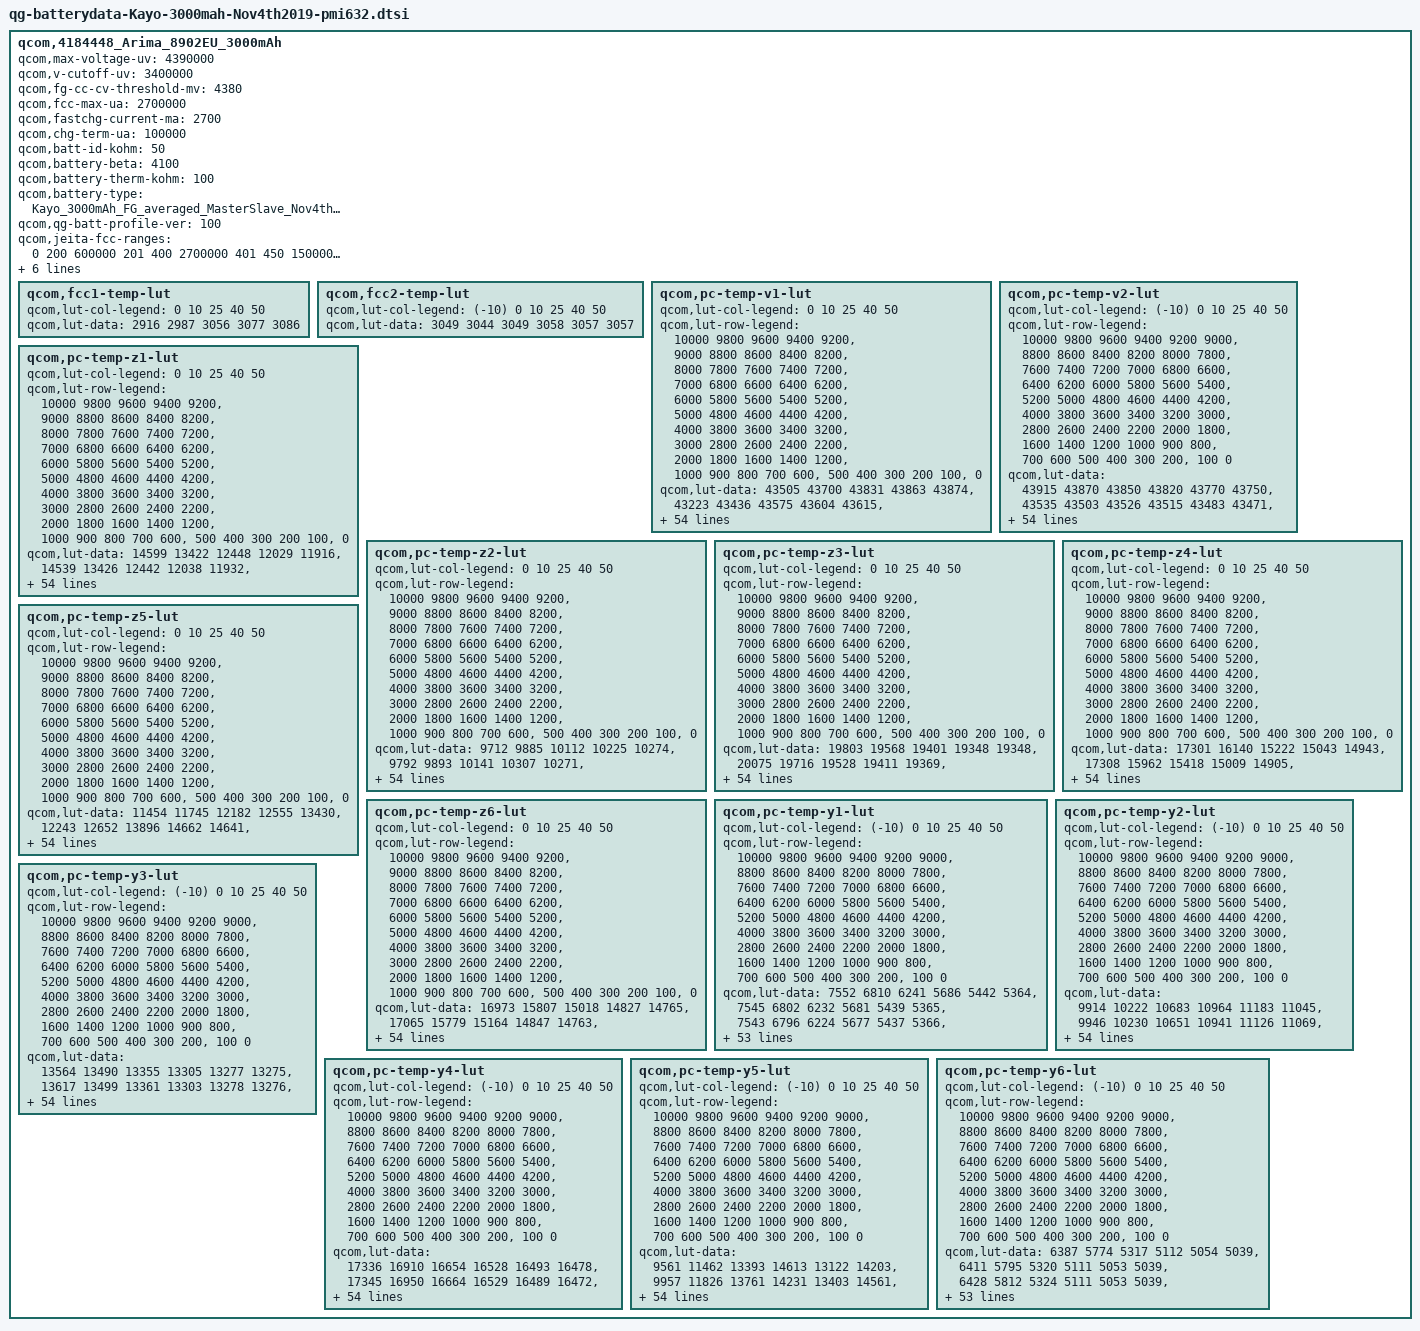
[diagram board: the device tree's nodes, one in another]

qcom,4184448_Arima_8902EU_3000mAh {
    /* 4184448_Arima_8902EU_3000mAh_averaged_MasterSlave_Nov4th2019 */
    qcom,max-voltage-uv = <4390000>;
    qcom,v-cutoff-uv = <3400000>;
    qcom,fg-cc-cv-threshold-mv = <4380>;
    qcom,fcc-max-ua = <2700000>;
    qcom,fastchg-current-ma = <2700>;
    qcom,chg-term-ua = <100000>;
    qcom,batt-id-kohm = <50>;
    qcom,battery-beta = <4100>;
    qcom,battery-therm-kohm = <100>;
    qcom,battery-type = "Kayo_3000mAh_FG_averaged_MasterSlave_Nov4th2019";
    qcom,qg-batt-profile-ver = <100>;

    qcom,jeita-fcc-ranges = <0   200   600000
                             201 400  2700000
                             401 450  1500000
                             451 550  1000000
                             551 600  0>;
    qcom,jeita-fv-ranges =  <0   200  4400000
                             201 400  4400000
                             401 450  4400000
                             451 550  4100000
                             551 600  3300000>;

    /* COOL = 20 DegC, WARM = 45 DegC */
    qcom,jeita-soft-thresholds = <0x3EBC 0x2204>;
    /* COLD = 0 DegC, HOT = 55 DegC */
    qcom,jeita-hard-thresholds = <0x5675 0x1987>;

    qcom,step-chg-ranges =  <3500000 4200000  2700000
                             4200001 4400000  1500000>;

	qcom,fcc1-temp-lut {
		qcom,lut-col-legend = <0 10 25 40 50>;
		qcom,lut-data = <2916 2987 3056 3077 3086>;
	};

	qcom,fcc2-temp-lut {
		qcom,lut-col-legend = <(-10) 0 10 25 40 50>;
		qcom,lut-data = <3049 3044 3049 3058 3057 3057>;
	};

	qcom,pc-temp-v1-lut {
		qcom,lut-col-legend = <0 10 25 40 50>;
		qcom,lut-row-legend = <10000 9800 9600 9400 9200>,
			<9000 8800 8600 8400 8200>,
			<8000 7800 7600 7400 7200>,
			<7000 6800 6600 6400 6200>,
			<6000 5800 5600 5400 5200>,
			<5000 4800 4600 4400 4200>,
			<4000 3800 3600 3400 3200>,
			<3000 2800 2600 2400 2200>,
			<2000 1800 1600 1400 1200>,
			<1000 900 800 700 600>,
			<500 400 300 200 100>,
			<0>;
		qcom,lut-data = <43505 43700 43831 43863 43874>,
			<43223 43436 43575 43604 43615>,
			<42972 43181 43325 43357 43374>,
			<42740 42936 43082 43121 43135>,
			<42513 42699 42840 42885 42899>,
			<42290 42465 42600 42648 42664>,
			<42072 42233 42363 42413 42432>,
			<41858 42006 42129 42179 42200>,
			<41647 41788 41899 41947 41970>,
			<41449 41575 41673 41719 41742>,
			<41275 41375 41449 41492 41515>,
			<41102 41200 41240 41272 41292>,
			<40890 41023 41056 41058 41076>,
			<40629 40803 40869 40853 40867>,
			<40376 40537 40638 40648 40663>,
			<40152 40296 40381 40446 40464>,
			<39950 40096 40175 40254 40274>,
			<39795 39922 40019 40078 40095>,
			<39678 39783 39875 39911 39925>,
			<39570 39672 39732 39752 39761>,
			<39450 39550 39589 39601 39607>,
			<39330 39403 39402 39421 39432>,
			<39209 39239 39142 39161 39196>,
			<39089 39046 38910 38917 38962>,
			<38970 38812 38757 38775 38807>,
			<38852 38639 38636 38670 38688>,
			<38735 38538 38540 38571 38578>,
			<38629 38463 38464 38475 38471>,
			<38529 38404 38394 38385 38374>,
			<38442 38358 38325 38300 38288>,
			<38382 38316 38262 38221 38211>,
			<38336 38275 38203 38152 38140>,
			<38298 38238 38150 38094 38075>,
			<38263 38204 38102 38040 38015>,
			<38232 38174 38062 37995 37962>,
			<38200 38141 38025 37953 37911>,
			<38170 38109 37989 37905 37853>,
			<38133 38072 37953 37854 37789>,
			<38079 38016 37902 37791 37717>,
			<38002 37926 37815 37710 37637>,
			<37909 37822 37708 37612 37545>,
			<37785 37705 37596 37502 37437>,
			<37643 37570 37468 37372 37309>,
			<37484 37410 37312 37219 37153>,
			<37344 37263 37166 37074 37009>,
			<37241 37162 37070 36982 36924>,
			<37211 37136 37044 36961 36902>,
			<37186 37117 37031 36946 36887>,
			<37160 37097 37013 36929 36872>,
			<37119 37062 36976 36885 36821>,
			<36940 36869 36767 36648 36564>,
			<36508 36448 36348 36223 36135>,
			<35949 35887 35785 35659 35574>,
			<35193 35123 35019 34892 34806>,
			<34002 33937 33832 33710 33623>,
			<30000 30000 30000 30000 30000>;
	};

	qcom,pc-temp-v2-lut {
		qcom,lut-col-legend = <(-10) 0 10 25 40 50>;
		qcom,lut-row-legend = <10000 9800 9600 9400 9200 9000>,
			<8800 8600 8400 8200 8000 7800>,
			<7600 7400 7200 7000 6800 6600>,
			<6400 6200 6000 5800 5600 5400>,
			<5200 5000 4800 4600 4400 4200>,
			<4000 3800 3600 3400 3200 3000>,
			<2800 2600 2400 2200 2000 1800>,
			<1600 1400 1200 1000 900 800>,
			<700 600 500 400 300 200>,
			<100 0>;
		qcom,lut-data = <43915 43870 43850 43820 43770 43750>,
			<43535 43503 43526 43515 43483 43471>,
			<43192 43171 43226 43231 43212 43205>,
			<42893 42880 42955 42969 42957 42954>,
			<42631 42624 42711 42728 42719 42717>,
			<42381 42377 42473 42491 42484 42483>,
			<42137 42128 42235 42256 42250 42250>,
			<41898 41886 42002 42023 42018 42018>,
			<41638 41652 41774 41795 41789 41789>,
			<41360 41423 41550 41569 41563 41564>,
			<41149 41218 41333 41347 41340 41341>,
			<41029 41055 41126 41127 41123 41123>,
			<40908 40891 40923 40915 40910 40909>,
			<40654 40662 40723 40720 40707 40705>,
			<40246 40370 40525 40536 40508 40506>,
			<39909 40095 40311 40337 40316 40315>,
			<39663 39845 40066 40107 40125 40128>,
			<39457 39615 39829 39895 39943 39949>,
			<39287 39422 39645 39742 39778 39783>,
			<39141 39249 39486 39614 39622 39623>,
			<38988 39077 39308 39444 39440 39439>,
			<38821 38900 39097 39205 39217 39219>,
			<38660 38734 38898 38976 39002 39007>,
			<38512 38588 38738 38797 38820 38826>,
			<38375 38456 38599 38642 38658 38665>,
			<38270 38332 38474 38513 38526 38532>,
			<38188 38210 38363 38405 38418 38423>,
			<38118 38110 38263 38308 38321 38325>,
			<38055 38039 38174 38217 38232 38234>,
			<37999 37982 38093 38134 38149 38150>,
			<37947 37935 38016 38061 38075 38074>,
			<37899 37897 37941 37993 38005 38002>,
			<37853 37861 37879 37930 37940 37936>,
			<37805 37827 37835 37869 37884 37880>,
			<37757 37793 37798 37812 37826 37821>,
			<37705 37751 37759 37755 37749 37733>,
			<37651 37702 37720 37698 37652 37610>,
			<37590 37647 37676 37636 37559 37500>,
			<37518 37583 37622 37565 37474 37411>,
			<37439 37509 37558 37488 37392 37328>,
			<37359 37421 37477 37410 37316 37250>,
			<37274 37316 37371 37325 37237 37170>,
			<37195 37197 37249 37215 37129 37062>,
			<37117 37071 37108 37079 36992 36926>,
			<37035 36961 36966 36930 36852 36793>,
			<36948 36867 36890 36881 36816 36763>,
			<36898 36819 36867 36867 36808 36752>,
			<36843 36772 36841 36853 36793 36736>,
			<36764 36701 36805 36823 36765 36710>,
			<36632 36595 36726 36763 36696 36625>,
			<36401 36395 36513 36551 36435 36335>,
			<36034 36017 36066 36101 35970 35860>,
			<35477 35437 35421 35504 35356 35242>,
			<34667 34604 34564 34707 34524 34396>,
			<33357 33266 33270 33533 33299 33148>,
			<29584 29579 29543 29540 29552 29553>;
	};

	qcom,pc-temp-z1-lut {
		qcom,lut-col-legend = <0 10 25 40 50>;
		qcom,lut-row-legend = <10000 9800 9600 9400 9200>,
			<9000 8800 8600 8400 8200>,
			<8000 7800 7600 7400 7200>,
			<7000 6800 6600 6400 6200>,
			<6000 5800 5600 5400 5200>,
			<5000 4800 4600 4400 4200>,
			<4000 3800 3600 3400 3200>,
			<3000 2800 2600 2400 2200>,
			<2000 1800 1600 1400 1200>,
			<1000 900 800 700 600>,
			<500 400 300 200 100>,
			<0>;
		qcom,lut-data = <14599 13422 12448 12029 11916>,
			<14539 13426 12442 12038 11932>,
			<14504 13419 12430 12034 11931>,
			<14480 13395 12421 12028 11929>,
			<14463 13354 12410 12025 11928>,
			<14447 13327 12396 12022 11929>,
			<14438 13311 12386 12020 11931>,
			<14441 13299 12379 12020 11932>,
			<14453 13289 12375 12021 11933>,
			<14459 13281 12375 12022 11934>,
			<14440 13277 12379 12022 11935>,
			<14406 13281 12381 12022 11936>,
			<14374 13285 12383 12024 11938>,
			<14335 13275 12384 12027 11941>,
			<14301 13247 12376 12027 11943>,
			<14274 13229 12357 12027 11944>,
			<14252 13221 12352 12027 11946>,
			<14250 13215 12360 12029 11948>,
			<14266 13222 12371 12033 11951>,
			<14280 13248 12379 12036 11953>,
			<14289 13268 12386 12039 11956>,
			<14303 13281 12392 12041 11958>,
			<14310 13291 12397 12042 11960>,
			<14326 13292 12401 12044 11961>,
			<14348 13290 12406 12047 11964>,
			<14369 13290 12412 12053 11968>,
			<14403 13309 12418 12058 11972>,
			<14418 13335 12424 12062 11976>,
			<14390 13338 12430 12067 11981>,
			<14356 13331 12437 12072 11985>,
			<14352 13331 12443 12077 11989>,
			<14358 13341 12450 12082 11992>,
			<14367 13353 12456 12086 11996>,
			<14380 13362 12463 12090 12000>,
			<14397 13370 12471 12095 12003>,
			<14416 13375 12480 12099 12006>,
			<14441 13382 12488 12103 12009>,
			<14462 13391 12496 12106 12011>,
			<14468 13404 12504 12109 12013>,
			<14469 13424 12511 12113 12016>,
			<14474 13437 12519 12117 12019>,
			<14490 13441 12525 12121 12022>,
			<14495 13445 12530 12125 12025>,
			<14477 13454 12538 12128 12028>,
			<14505 13478 12547 12133 12032>,
			<14495 13462 12558 12136 12033>,
			<14465 13457 12554 12138 12034>,
			<14488 13470 12557 12139 12036>,
			<14524 13460 12560 12141 12037>,
			<14513 13470 12566 12144 12040>,
			<14515 13503 12576 12150 12046>,
			<14537 13510 12589 12161 12053>,
			<14588 13546 12611 12175 12068>,
			<14625 13621 12652 12200 12088>,
			<14625 13621 12652 12200 12088>,
			<14625 13621 12652 12200 12088>;
	};

	qcom,pc-temp-z2-lut {
		qcom,lut-col-legend = <0 10 25 40 50>;
		qcom,lut-row-legend = <10000 9800 9600 9400 9200>,
			<9000 8800 8600 8400 8200>,
			<8000 7800 7600 7400 7200>,
			<7000 6800 6600 6400 6200>,
			<6000 5800 5600 5400 5200>,
			<5000 4800 4600 4400 4200>,
			<4000 3800 3600 3400 3200>,
			<3000 2800 2600 2400 2200>,
			<2000 1800 1600 1400 1200>,
			<1000 900 800 700 600>,
			<500 400 300 200 100>,
			<0>;
		qcom,lut-data = <9712 9885 10112 10225 10274>,
			<9792 9893 10141 10307 10271>,
			<9825 9895 10133 10369 10364>,
			<9845 9888 10112 10341 10395>,
			<9860 9865 10090 10310 10403>,
			<9873 9846 10063 10269 10370>,
			<9881 9834 10046 10241 10329>,
			<9879 9826 10039 10243 10320>,
			<9870 9826 10036 10252 10316>,
			<9860 9826 10044 10264 10310>,
			<9853 9827 10063 10282 10288>,
			<9843 9840 10079 10296 10267>,
			<9825 9856 10092 10291 10258>,
			<9789 9861 10105 10275 10255>,
			<9767 9862 10122 10264 10264>,
			<9768 9865 10140 10241 10282>,
			<9770 9879 10151 10233 10304>,
			<9776 9901 10158 10243 10333>,
			<9796 9923 10164 10256 10364>,
			<9810 9949 10177 10268 10383>,
			<9805 9965 10195 10282 10398>,
			<9793 9972 10203 10305 10403>,
			<9785 9976 10206 10367 10381>,
			<9781 9978 10206 10419 10355>,
			<9779 9979 10189 10387 10375>,
			<9781 9981 10163 10306 10447>,
			<9788 9986 10160 10287 10494>,
			<9795 9992 10174 10329 10528>,
			<9802 9992 10187 10361 10545>,
			<9807 9989 10205 10357 10449>,
			<9812 9987 10223 10347 10264>,
			<9815 9991 10222 10333 10218>,
			<9819 9997 10208 10311 10224>,
			<9824 10003 10201 10300 10234>,
			<9830 10008 10205 10325 10274>,
			<9838 10014 10212 10371 10343>,
			<9852 10020 10217 10413 10412>,
			<9867 10027 10226 10458 10494>,
			<9881 10036 10238 10490 10530>,
			<9895 10047 10268 10511 10526>,
			<9909 10057 10292 10523 10518>,
			<9922 10062 10289 10521 10514>,
			<9942 10068 10281 10514 10512>,
			<9986 10083 10287 10466 10501>,
			<10168 10194 10324 10440 10492>,
			<10204 10275 10381 10463 10512>,
			<10117 10323 10371 10461 10519>,
			<10078 10427 10370 10454 10521>,
			<10040 10550 10407 10447 10559>,
			<10045 10586 10407 10549 10754>,
			<10031 10491 10568 10539 10410>,
			<10023 10462 10575 10439 10280>,
			<9876 10362 10543 10309 10300>,
			<9730 10231 10462 10272 10258>,
			<9730 10231 10462 10272 10258>,
			<9730 10231 10462 10272 10258>;
	};

	qcom,pc-temp-z3-lut {
		qcom,lut-col-legend = <0 10 25 40 50>;
		qcom,lut-row-legend = <10000 9800 9600 9400 9200>,
			<9000 8800 8600 8400 8200>,
			<8000 7800 7600 7400 7200>,
			<7000 6800 6600 6400 6200>,
			<6000 5800 5600 5400 5200>,
			<5000 4800 4600 4400 4200>,
			<4000 3800 3600 3400 3200>,
			<3000 2800 2600 2400 2200>,
			<2000 1800 1600 1400 1200>,
			<1000 900 800 700 600>,
			<500 400 300 200 100>,
			<0>;
		qcom,lut-data = <19803 19568 19401 19348 19348>,
			<20075 19716 19528 19411 19369>,
			<20081 19811 19562 19454 19411>,
			<20062 19834 19578 19464 19433>,
			<20034 19844 19582 19468 19440>,
			<19966 19847 19584 19469 19440>,
			<19907 19848 19584 19470 19440>,
			<19901 19848 19574 19463 19434>,
			<19900 19843 19559 19448 19417>,
			<19900 19825 19547 19436 19406>,
			<19899 19804 19534 19427 19401>,
			<19898 19774 19526 19420 19396>,
			<19910 19745 19516 19414 19385>,
			<19966 19736 19507 19404 19372>,
			<20004 19733 19504 19397 19367>,
			<19994 19728 19503 19385 19365>,
			<19971 19712 19499 19378 19363>,
			<19943 19687 19487 19377 19355>,
			<19899 19665 19475 19375 19344>,
			<19869 19642 19470 19374 19342>,
			<19877 19632 19466 19372 19342>,
			<19901 19647 19469 19372 19343>,
			<19923 19671 19495 19388 19349>,
			<19942 19689 19514 19404 19356>,
			<19958 19707 19506 19392 19349>,
			<19971 19715 19491 19363 19328>,
			<19982 19714 19480 19354 19324>,
			<19987 19712 19471 19361 19367>,
			<19987 19708 19467 19371 19406>,
			<19986 19700 19472 19393 19402>,
			<19981 19693 19482 19420 19389>,
			<19964 19687 19491 19424 19380>,
			<19944 19681 19501 19417 19375>,
			<19927 19674 19505 19408 19370>,
			<19909 19667 19502 19400 19364>,
			<19887 19661 19496 19393 19359>,
			<19857 19654 19490 19391 19359>,
			<19833 19648 19482 19390 19361>,
			<19823 19645 19476 19388 19361>,
			<19817 19642 19472 19384 19360>,
			<19809 19639 19469 19380 19357>,
			<19799 19633 19467 19379 19354>,
			<19782 19623 19464 19379 19350>,
			<19746 19608 19456 19370 19351>,
			<19539 19554 19438 19361 19350>,
			<19448 19517 19424 19359 19336>,
			<19360 19487 19421 19353 19336>,
			<19338 19415 19383 19350 19334>,
			<19334 19359 19380 19350 19322>,
			<19331 19356 19379 19342 19311>,
			<19336 19407 19355 19344 19349>,
			<19363 19368 19347 19351 19359>,
			<19378 19358 19345 19361 19341>,
			<19370 19355 19344 19360 19341>,
			<19370 19355 19344 19360 19341>,
			<19370 19355 19344 19360 19341>;
	};

	qcom,pc-temp-z4-lut {
		qcom,lut-col-legend = <0 10 25 40 50>;
		qcom,lut-row-legend = <10000 9800 9600 9400 9200>,
			<9000 8800 8600 8400 8200>,
			<8000 7800 7600 7400 7200>,
			<7000 6800 6600 6400 6200>,
			<6000 5800 5600 5400 5200>,
			<5000 4800 4600 4400 4200>,
			<4000 3800 3600 3400 3200>,
			<3000 2800 2600 2400 2200>,
			<2000 1800 1600 1400 1200>,
			<1000 900 800 700 600>,
			<500 400 300 200 100>,
			<0>;
		qcom,lut-data = <17301 16140 15222 15043 14943>,
			<17308 15962 15418 15009 14905>,
			<17122 15786 15328 15050 14950>,
			<16727 15606 15162 14976 14903>,
			<16433 15424 15062 14917 14859>,
			<16251 15281 14992 14877 14826>,
			<16097 15174 14938 14845 14801>,
			<15952 15090 14895 14822 14787>,
			<15818 15031 14862 14805 14779>,
			<15698 14987 14843 14793 14770>,
			<15592 14949 14829 14783 14761>,
			<15496 14907 14817 14775 14753>,
			<15401 14876 14803 14767 14749>,
			<15307 14870 14793 14758 14746>,
			<15235 14869 14788 14757 14740>,
			<15190 14866 14784 14753 14727>,
			<15156 14857 14776 14747 14716>,
			<15122 14842 14753 14733 14710>,
			<15093 14830 14734 14716 14706>,
			<15061 14817 14728 14709 14701>,
			<15019 14806 14725 14705 14695>,
			<14971 14793 14734 14708 14694>,
			<14933 14784 14809 14785 14760>,
			<14900 14807 14876 14871 14845>,
			<14879 14900 14900 14891 14870>,
			<14875 14951 14915 14901 14882>,
			<14873 14946 14914 14901 14881>,
			<14874 14934 14897 14876 14817>,
			<14882 14919 14874 14840 14752>,
			<14892 14896 14848 14796 14738>,
			<14893 14874 14819 14748 14730>,
			<14887 14854 14793 14729 14721>,
			<14880 14837 14768 14720 14708>,
			<14873 14820 14753 14716 14702>,
			<14865 14805 14745 14714 14702>,
			<14862 14792 14740 14713 14703>,
			<14861 14779 14737 14715 14707>,
			<14860 14769 14734 14723 14723>,
			<14851 14768 14734 14731 14732>,
			<14832 14769 14745 14740 14734>,
			<14825 14770 14755 14747 14735>,
			<14824 14765 14748 14740 14731>,
			<14823 14760 14735 14728 14721>,
			<14824 14761 14737 14735 14723>,
			<14909 14753 14731 14734 14720>,
			<14962 14738 14704 14705 14702>,
			<15055 14759 14693 14694 14688>,
			<15069 14828 14716 14674 14667>,
			<15067 14881 14704 14652 14654>,
			<15059 14879 14702 14660 14665>,
			<15048 14832 14755 14694 14659>,
			<15060 14897 14775 14692 14655>,
			<15071 14921 14782 14684 14675>,
			<15107 14937 14788 14688 14676>,
			<15107 14937 14788 14688 14676>,
			<15107 14937 14788 14688 14676>;
	};

	qcom,pc-temp-z5-lut {
		qcom,lut-col-legend = <0 10 25 40 50>;
		qcom,lut-row-legend = <10000 9800 9600 9400 9200>,
			<9000 8800 8600 8400 8200>,
			<8000 7800 7600 7400 7200>,
			<7000 6800 6600 6400 6200>,
			<6000 5800 5600 5400 5200>,
			<5000 4800 4600 4400 4200>,
			<4000 3800 3600 3400 3200>,
			<3000 2800 2600 2400 2200>,
			<2000 1800 1600 1400 1200>,
			<1000 900 800 700 600>,
			<500 400 300 200 100>,
			<0>;
		qcom,lut-data = <11454 11745 12182 12555 13430>,
			<12243 12652 13896 14662 14641>,
			<12436 13367 14441 15536 15665>,
			<12532 13830 14827 15834 16844>,
			<12552 14152 15222 16091 17560>,
			<12527 14535 15609 16368 17875>,
			<12502 15138 15928 16601 18050>,
			<12551 15743 16212 16735 17898>,
			<12726 16087 16403 16725 17371>,
			<12887 16332 16498 16662 17155>,
			<12979 16550 16698 16583 17268>,
			<13082 16850 16825 16576 17355>,
			<13409 17177 17092 16656 16992>,
			<14282 17631 17333 16659 16294>,
			<14830 18572 17534 16467 16225>,
			<14822 19041 18085 15934 16905>,
			<14790 18616 18533 15813 17373>,
			<14713 18031 18902 16522 17104>,
			<14449 17791 19349 17525 16697>,
			<14245 17646 19899 18215 16853>,
			<14598 17636 20709 18771 17988>,
			<15691 20478 23295 19826 18918>,
			<17030 25517 32932 23676 19820>,
			<18860 30303 39368 27018 20550>,
			<21143 35691 34703 24339 19129>,
			<23928 38044 26187 17537 15121>,
			<27393 36280 21987 15112 13807>,
			<30042 33236 19473 14804 16059>,
			<32020 30881 18529 14686 18244>,
			<33389 28692 18785 16275 18450>,
			<33081 27358 19394 19654 18492>,
			<30672 26749 20802 21861 18808>,
			<28094 26332 24167 23393 20141>,
			<26285 26063 26973 24608 21754>,
			<24607 25796 29058 25724 23548>,
			<22853 25708 30393 26520 25129>,
			<20734 25757 30186 26653 25308>,
			<19445 25839 29114 26586 25032>,
			<19728 26174 27935 26310 24544>,
			<20483 27216 26468 23530 22587>,
			<20945 27813 25238 20623 20253>,
			<21181 26835 24812 20503 19350>,
			<21204 25242 24404 20657 18824>,
			<20042 23391 22263 18651 18178>,
			<15624 21181 21039 17430 17655>,
			<13453 19868 21195 18547 16954>,
			<11648 17113 21109 18133 17459>,
			<11421 13549 15913 18875 18995>,
			<11379 12104 15838 21530 18855>,
			<11375 12108 15893 19283 16193>,
			<11506 13512 13714 15340 18602>,
			<11658 12181 12915 15355 19788>,
			<11612 11862 12663 15997 15501>,
			<11332 11678 12471 15399 15001>,
			<11332 11678 12471 15399 15001>,
			<11332 11678 12471 15399 15001>;
	};

	qcom,pc-temp-z6-lut {
		qcom,lut-col-legend = <0 10 25 40 50>;
		qcom,lut-row-legend = <10000 9800 9600 9400 9200>,
			<9000 8800 8600 8400 8200>,
			<8000 7800 7600 7400 7200>,
			<7000 6800 6600 6400 6200>,
			<6000 5800 5600 5400 5200>,
			<5000 4800 4600 4400 4200>,
			<4000 3800 3600 3400 3200>,
			<3000 2800 2600 2400 2200>,
			<2000 1800 1600 1400 1200>,
			<1000 900 800 700 600>,
			<500 400 300 200 100>,
			<0>;
		qcom,lut-data = <16973 15807 15018 14827 14765>,
			<17065 15779 15164 14847 14763>,
			<16980 15735 15135 14883 14799>,
			<16753 15671 15074 14859 14791>,
			<16567 15579 15033 14838 14782>,
			<16430 15503 15001 14823 14772>,
			<16316 15449 14974 14808 14760>,
			<16229 15404 14948 14793 14748>,
			<16160 15366 14926 14779 14736>,
			<16098 15334 14911 14767 14727>,
			<16041 15303 14899 14759 14720>,
			<15989 15268 14889 14751 14714>,
			<15949 15238 14879 14743 14707>,
			<15916 15223 14869 14736 14699>,
			<15884 15215 14863 14729 14692>,
			<15850 15206 14857 14722 14686>,
			<15816 15191 14849 14715 14680>,
			<15783 15173 14834 14707 14673>,
			<15748 15158 14822 14701 14666>,
			<15725 15144 14818 14697 14663>,
			<15719 15138 14816 14695 14660>,
			<15716 15143 14822 14696 14660>,
			<15716 15153 14871 14740 14695>,
			<15717 15177 14908 14785 14735>,
			<15720 15227 14913 14785 14738>,
			<15724 15253 14914 14778 14736>,
			<15733 15252 14911 14772 14734>,
			<15741 15248 14900 14765 14730>,
			<15748 15243 14889 14758 14724>,
			<15754 15231 14882 14752 14717>,
			<15753 15219 14876 14746 14708>,
			<15745 15210 14870 14740 14699>,
			<15735 15201 14866 14733 14692>,
			<15727 15194 14862 14727 14686>,
			<15719 15186 14858 14722 14683>,
			<15710 15181 14855 14718 14680>,
			<15700 15176 14851 14718 14682>,
			<15693 15173 14847 14721 14689>,
			<15690 15173 14846 14724 14694>,
			<15687 15178 14850 14725 14694>,
			<15687 15181 14854 14727 14693>,
			<15688 15180 14851 14725 14690>,
			<15688 15179 14846 14720 14685>,
			<15677 15176 14844 14719 14686>,
			<15623 15154 14835 14714 14685>,
			<15600 15133 14818 14701 14671>,
			<15596 15128 14812 14694 14664>,
			<15593 15123 14803 14684 14654>,
			<15591 15118 14797 14674 14642>,
			<15592 15120 14796 14674 14642>,
			<15601 15133 14809 14690 14660>,
			<15634 15150 14818 14696 14667>,
			<15666 15168 14825 14701 14669>,
			<15707 15193 14837 14707 14674>,
			<15707 15193 14837 14707 14674>,
			<15707 15193 14837 14707 14674>;
	};

	qcom,pc-temp-y1-lut {
		qcom,lut-col-legend = <(-10) 0 10 25 40 50>;
		qcom,lut-row-legend = <10000 9800 9600 9400 9200 9000>,
			<8800 8600 8400 8200 8000 7800>,
			<7600 7400 7200 7000 6800 6600>,
			<6400 6200 6000 5800 5600 5400>,
			<5200 5000 4800 4600 4400 4200>,
			<4000 3800 3600 3400 3200 3000>,
			<2800 2600 2400 2200 2000 1800>,
			<1600 1400 1200 1000 900 800>,
			<700 600 500 400 300 200>,
			<100 0>;
		qcom,lut-data = <7552 6810 6241 5686 5442 5364>,
			<7545 6802 6232 5681 5439 5365>,
			<7543 6796 6224 5677 5437 5366>,
			<7546 6794 6215 5672 5434 5367>,
			<7553 6793 6208 5668 5432 5367>,
			<7561 6793 6202 5664 5430 5367>,
			<7572 6804 6199 5660 5429 5367>,
			<7581 6819 6195 5656 5427 5366>,
			<7576 6820 6192 5654 5427 5366>,
			<7550 6812 6189 5652 5426 5366>,
			<7540 6808 6187 5649 5425 5367>,
			<7553 6811 6186 5648 5425 5367>,
			<7568 6816 6186 5646 5424 5367>,
			<7570 6816 6186 5644 5424 5368>,
			<7562 6813 6184 5642 5424 5370>,
			<7564 6815 6183 5642 5425 5371>,
			<7576 6837 6188 5650 5426 5372>,
			<7587 6859 6195 5657 5427 5373>,
			<7588 6854 6198 5656 5427 5373>,
			<7579 6834 6203 5655 5428 5373>,
			<7572 6826 6206 5655 5429 5374>,
			<7556 6818 6208 5656 5431 5375>,
			<7544 6814 6209 5658 5432 5375>,
			<7553 6824 6207 5662 5434 5377>,
			<7570 6842 6203 5666 5435 5380>,
			<7573 6846 6202 5670 5437 5381>,
			<7567 6832 6209 5674 5440 5383>,
			<7559 6821 6217 5679 5443 5384>,
			<7555 6821 6225 5684 5445 5386>,
			<7555 6822 6231 5690 5448 5388>,
			<7553 6823 6235 5695 5451 5390>,
			<7541 6824 6242 5700 5455 5393>,
			<7532 6824 6249 5706 5458 5396>,
			<7541 6826 6256 5712 5461 5399>,
			<7554 6829 6262 5718 5464 5401>,
			<7555 6829 6265 5725 5467 5403>,
			<7551 6826 6262 5734 5471 5405>,
			<7546 6825 6258 5738 5474 5408>,
			<7535 6832 6263 5739 5475 5411>,
			<7526 6841 6270 5740 5476 5414>,
			<7539 6844 6274 5742 5479 5415>,
			<7576 6860 6278 5746 5482 5415>,
			<7552 6858 6295 5752 5483 5416>,
			<7527 6841 6309 5758 5486 5418>,
			<7601 6836 6293 5763 5490 5421>,
			<7546 6867 6308 5765 5492 5421>,
			<7555 6871 6310 5772 5494 5424>,
			<7582 6861 6320 5779 5494 5424>,
			<7584 6849 6325 5788 5497 5425>,
			<7612 6861 6321 5791 5498 5425>,
			<7599 6858 6326 5796 5500 5427>,
			<7691 6876 6346 5806 5508 5435>,
			<7678 6902 6371 5830 5519 5444>,
			<7757 6955 6381 5870 5536 5456>,
			<7757 6955 6381 5870 5536 5456>,
			<7757 6955 6381 5870 5536 5456>;
	};

	qcom,pc-temp-y2-lut {
		qcom,lut-col-legend = <(-10) 0 10 25 40 50>;
		qcom,lut-row-legend = <10000 9800 9600 9400 9200 9000>,
			<8800 8600 8400 8200 8000 7800>,
			<7600 7400 7200 7000 6800 6600>,
			<6400 6200 6000 5800 5600 5400>,
			<5200 5000 4800 4600 4400 4200>,
			<4000 3800 3600 3400 3200 3000>,
			<2800 2600 2400 2200 2000 1800>,
			<1600 1400 1200 1000 900 800>,
			<700 600 500 400 300 200>,
			<100 0>;
		qcom,lut-data = <9914 10222 10683 10964 11183 11045>,
			<9946 10230 10651 10941 11126 11069>,
			<9983 10240 10621 10918 11071 11067>,
			<10020 10249 10593 10895 11020 11052>,
			<10050 10257 10567 10872 10975 11035>,
			<10068 10262 10544 10849 10941 11028>,
			<10074 10265 10523 10825 10911 11019>,
			<10079 10267 10506 10802 10890 11002>,
			<10101 10266 10496 10774 10887 10976>,
			<10158 10263 10488 10742 10895 10930>,
			<10213 10263 10483 10729 10900 10910>,
			<10266 10342 10478 10738 10902 10910>,
			<10305 10434 10476 10748 10902 10910>,
			<10314 10433 10492 10751 10898 10920>,
			<10318 10403 10543 10754 10887 10947>,
			<10326 10392 10576 10759 10885 10954>,
			<10351 10419 10589 10776 10908 10926>,
			<10387 10455 10601 10800 10946 10901>,
			<10432 10476 10615 10843 10994 10928>,
			<10484 10492 10630 10897 11052 10992>,
			<10484 10511 10647 10908 11086 11025>,
			<10286 10534 10664 10894 11107 11052>,
			<10094 10558 10683 10883 11119 11075>,
			<9952 10585 10701 10892 11121 11108>,
			<9736 10611 10721 10911 11120 11155>,
			<9680 10616 10741 10926 11122 11189>,
			<9673 10605 10765 10949 11123 11222>,
			<9668 10592 10780 10972 11125 11238>,
			<9666 10579 10784 10989 11140 11234>,
			<9664 10561 10786 11002 11163 11228>,
			<9663 10538 10790 11008 11178 11230>,
			<9661 10508 10798 11010 11191 11244>,
			<9660 10466 10803 11011 11200 11260>,
			<9659 10335 10790 11004 11211 11279>,
			<9658 10135 10767 10993 11219 11295>,
			<9657 10006 10747 10986 11196 11289>,
			<9655 9805 10727 10977 11126 11262>,
			<9655 9695 10703 10967 11096 11241>,
			<9654 9677 10673 10957 11113 11231>,
			<9653 9667 10636 10946 11131 11227>,
			<9653 9661 10595 10934 11116 11220>,
			<9652 9658 10547 10920 11077 11193>,
			<9652 9656 10487 10904 11077 11137>,
			<9652 9653 10419 10885 11093 11129>,
			<9651 9652 10290 10865 11083 11158>,
			<9651 9652 10140 10837 11039 11066>,
			<9651 9651 10260 10820 10979 10993>,
			<9651 9651 10216 10799 10953 10940>,
			<9651 9651 10188 10795 10964 10908>,
			<9650 9650 10170 10774 10960 10865>,
			<9650 9650 10144 10741 10924 10853>,
			<9649 9650 9941 10682 10864 10805>,
			<9648 9649 9709 10605 10800 10758>,
			<9647 9648 9665 10555 10732 10653>,
			<9647 9648 9665 10555 10732 10653>,
			<9647 9648 9665 10555 10732 10653>;
	};

	qcom,pc-temp-y3-lut {
		qcom,lut-col-legend = <(-10) 0 10 25 40 50>;
		qcom,lut-row-legend = <10000 9800 9600 9400 9200 9000>,
			<8800 8600 8400 8200 8000 7800>,
			<7600 7400 7200 7000 6800 6600>,
			<6400 6200 6000 5800 5600 5400>,
			<5200 5000 4800 4600 4400 4200>,
			<4000 3800 3600 3400 3200 3000>,
			<2800 2600 2400 2200 2000 1800>,
			<1600 1400 1200 1000 900 800>,
			<700 600 500 400 300 200>,
			<100 0>;
		qcom,lut-data = <13564 13490 13355 13305 13277 13275>,
			<13617 13499 13361 13303 13278 13276>,
			<13666 13512 13367 13302 13280 13277>,
			<13707 13527 13372 13301 13282 13278>,
			<13735 13539 13377 13301 13283 13279>,
			<13744 13545 13381 13302 13284 13280>,
			<13734 13546 13384 13303 13284 13281>,
			<13717 13547 13386 13304 13285 13282>,
			<13707 13555 13388 13304 13285 13283>,
			<13699 13577 13389 13302 13285 13283>,
			<13686 13587 13391 13302 13286 13283>,
			<13638 13554 13394 13308 13290 13283>,
			<13591 13513 13397 13316 13295 13283>,
			<13592 13504 13398 13319 13295 13285>,
			<13607 13500 13401 13321 13294 13289>,
			<13611 13496 13402 13322 13294 13291>,
			<13582 13489 13399 13324 13296 13289>,
			<13549 13479 13393 13326 13298 13288>,
			<13536 13470 13388 13326 13300 13289>,
			<13527 13460 13382 13327 13301 13291>,
			<13514 13451 13375 13326 13301 13292>,
			<13488 13442 13368 13321 13297 13288>,
			<13467 13432 13361 13315 13293 13283>,
			<13461 13421 13356 13309 13288 13280>,
			<13459 13409 13352 13303 13284 13278>,
			<13456 13398 13348 13301 13282 13277>,
			<13449 13388 13344 13300 13281 13277>,
			<13445 13380 13342 13300 13281 13276>,
			<13452 13373 13342 13300 13282 13277>,
			<13468 13368 13344 13301 13283 13278>,
			<13489 13368 13343 13302 13284 13278>,
			<13523 13374 13338 13306 13284 13278>,
			<13561 13381 13335 13307 13284 13278>,
			<13598 13391 13338 13307 13285 13279>,
			<13641 13402 13343 13307 13286 13280>,
			<13695 13412 13344 13306 13286 13279>,
			<13766 13428 13344 13306 13285 13277>,
			<13844 13447 13344 13305 13285 13276>,
			<13929 13471 13348 13303 13283 13276>,
			<14023 13502 13352 13301 13282 13276>,
			<14128 13548 13355 13300 13282 13277>,
			<14249 13625 13357 13300 13284 13278>,
			<14381 13738 13361 13300 13284 13278>,
			<14524 13900 13364 13301 13283 13278>,
			<14576 14042 13355 13301 13282 13277>,
			<14696 14187 13357 13304 13281 13279>,
			<14828 14350 13379 13307 13288 13282>,
			<14982 14536 13393 13314 13290 13285>,
			<15128 14688 13413 13314 13293 13290>,
			<15291 14820 13436 13324 13301 13291>,
			<15495 14916 13453 13326 13297 13287>,
			<16003 15021 13463 13324 13297 13287>,
			<16900 15292 13520 13334 13299 13291>,
			<18414 16030 13693 13348 13304 13295>,
			<18414 16030 13693 13348 13304 13295>,
			<18414 16030 13693 13348 13304 13295>;
	};

	qcom,pc-temp-y4-lut {
		qcom,lut-col-legend = <(-10) 0 10 25 40 50>;
		qcom,lut-row-legend = <10000 9800 9600 9400 9200 9000>,
			<8800 8600 8400 8200 8000 7800>,
			<7600 7400 7200 7000 6800 6600>,
			<6400 6200 6000 5800 5600 5400>,
			<5200 5000 4800 4600 4400 4200>,
			<4000 3800 3600 3400 3200 3000>,
			<2800 2600 2400 2200 2000 1800>,
			<1600 1400 1200 1000 900 800>,
			<700 600 500 400 300 200>,
			<100 0>;
		qcom,lut-data = <17336 16910 16654 16528 16493 16478>,
			<17345 16950 16664 16529 16489 16472>,
			<17360 17005 16676 16531 16486 16469>,
			<17381 17063 16687 16534 16484 16467>,
			<17406 17111 16697 16537 16484 16466>,
			<17436 17135 16702 16541 16484 16466>,
			<17481 17143 16704 16544 16486 16467>,
			<17521 17148 16706 16548 16491 16469>,
			<17513 17139 16712 16557 16497 16473>,
			<17470 17104 16727 16572 16504 16478>,
			<17459 17092 16742 16580 16508 16483>,
			<17755 17309 16753 16581 16509 16491>,
			<18088 17561 16766 16582 16510 16498>,
			<17958 17551 16815 16591 16517 16502>,
			<17483 17428 16913 16615 16533 16505>,
			<17227 17302 16949 16639 16547 16510>,
			<17152 17162 16927 16660 16558 16522>,
			<17111 17048 16899 16684 16570 16539>,
			<17097 17011 16885 16729 16597 16559>,
			<17088 16991 16873 16782 16631 16581>,
			<17080 16960 16846 16784 16637 16584>,
			<17062 16899 16748 16691 16606 16566>,
			<17049 16842 16657 16597 16566 16541>,
			<17037 16811 16626 16552 16527 16511>,
			<17009 16787 16606 16520 16491 16481>,
			<17003 16757 16600 16515 16484 16475>,
			<17010 16710 16599 16517 16487 16477>,
			<17017 16681 16598 16519 16491 16481>,
			<17024 16688 16598 16523 16497 16486>,
			<17030 16703 16597 16529 16505 16495>,
			<17032 16714 16595 16536 16516 16504>,
			<17032 16722 16591 16544 16529 16517>,
			<17032 16731 16588 16551 16542 16529>,
			<17037 16752 16591 16558 16557 16544>,
			<17043 16787 16596 16562 16569 16556>,
			<17045 16818 16605 16560 16557 16543>,
			<17047 16862 16620 16550 16515 16500>,
			<17047 16896 16633 16539 16491 16478>,
			<17044 16920 16644 16524 16483 16474>,
			<17040 16937 16653 16513 16480 16472>,
			<17042 16938 16659 16518 16485 16476>,
			<17050 16933 16664 16530 16495 16484>,
			<17067 16920 16673 16537 16496 16484>,
			<17092 16909 16677 16539 16494 16481>,
			<17104 16907 16671 16514 16472 16460>,
			<17107 16918 16696 16522 16490 16475>,
			<17141 16963 16691 16540 16499 16485>,
			<17180 17018 16736 16559 16512 16499>,
			<17223 17102 16796 16588 16529 16521>,
			<17257 17205 16887 16618 16545 16531>,
			<17284 17261 16939 16607 16502 16483>,
			<17442 17263 16943 16591 16494 16478>,
			<17801 17305 16996 16625 16510 16492>,
			<18794 17772 17141 16709 16559 16537>,
			<18794 17772 17141 16709 16559 16537>,
			<18794 17772 17141 16709 16559 16537>;
	};

	qcom,pc-temp-y5-lut {
		qcom,lut-col-legend = <(-10) 0 10 25 40 50>;
		qcom,lut-row-legend = <10000 9800 9600 9400 9200 9000>,
			<8800 8600 8400 8200 8000 7800>,
			<7600 7400 7200 7000 6800 6600>,
			<6400 6200 6000 5800 5600 5400>,
			<5200 5000 4800 4600 4400 4200>,
			<4000 3800 3600 3400 3200 3000>,
			<2800 2600 2400 2200 2000 1800>,
			<1600 1400 1200 1000 900 800>,
			<700 600 500 400 300 200>,
			<100 0>;
		qcom,lut-data = <9561 11462 13393 14613 13122 14203>,
			<9957 11826 13761 14231 13403 14561>,
			<10618 12421 14121 13799 13565 14776>,
			<11343 13062 14429 13377 13638 14881>,
			<11936 13568 14640 13030 13650 14906>,
			<12198 13754 14711 12818 13629 14882>,
			<12254 13708 14658 12725 13485 14774>,
			<12284 13647 14543 12646 13248 14586>,
			<12201 13889 14333 12429 12994 14346>,
			<11891 14806 13915 12024 12697 14004>,
			<11748 15214 13562 11873 12606 13650>,
			<11989 13951 13266 12314 13123 13214>,
			<12478 12499 13067 12783 13673 12899>,
			<13614 13075 13078 12724 13468 13090>,
			<15670 15217 13175 12491 12829 13652>,
			<16335 16082 13356 12416 12608 13810>,
			<14952 15650 14131 12486 12710 13221>,
			<13612 15209 15044 12618 12838 12684>,
			<13802 15292 15557 12917 12912 12716>,
			<14381 15573 15951 13533 12986 12878>,
			<14504 15710 16197 14452 13314 13166>,
			<13761 15755 16381 16253 14962 13950>,
			<12935 15775 16472 17409 16182 14687>,
			<12235 15674 16267 16729 15958 15068>,
			<11340 15417 15775 15439 15458 15333>,
			<11015 15120 15370 14948 15046 15286>,
			<10875 14344 14909 14766 14607 14758>,
			<10796 13500 14656 14670 14389 14416>,
			<10768 12866 15021 14698 14575 14530>,
			<10751 12339 15579 14865 14855 14693>,
			<10767 12262 15511 15302 14928 14662>,
			<10867 12492 14847 16313 14894 14420>,
			<10973 12673 14461 16966 14961 14292>,
			<11046 12827 14863 17184 15410 14669>,
			<11116 12947 15446 17313 16009 15211>,
			<11204 12748 15461 17316 16488 15448>,
			<11313 12067 15082 17145 16940 15612>,
			<11359 11737 14859 16910 17040 15654>,
			<11304 11697 15027 16281 16164 15541>,
			<11202 11634 15240 15482 15226 15343>,
			<11077 11632 15141 14907 15093 15094>,
			<10923 11665 14782 14443 15099 14773>,
			<10879 11630 14532 14078 14642 14517>,
			<10913 11485 14265 14000 14412 14404>,
			<10872 11371 13177 14806 15169 15860>,
			<11038 11318 12659 14742 13466 14171>,
			<11078 11212 13426 14374 14372 13964>,
			<11252 11405 13433 14745 13876 14003>,
			<11425 11431 13705 13712 13947 14775>,
			<11572 11839 14106 14341 15142 14609>,
			<11569 12340 14307 15209 16090 15443>,
			<11194 12346 13428 15199 17270 15675>,
			<10507 11656 11893 15949 16875 17050>,
			<9839 10544 11476 16641 17739 18076>,
			<9839 10544 11476 16641 17739 18076>,
			<9839 10544 11476 16641 17739 18076>;
	};

	qcom,pc-temp-y6-lut {
		qcom,lut-col-legend = <(-10) 0 10 25 40 50>;
		qcom,lut-row-legend = <10000 9800 9600 9400 9200 9000>,
			<8800 8600 8400 8200 8000 7800>,
			<7600 7400 7200 7000 6800 6600>,
			<6400 6200 6000 5800 5600 5400>,
			<5200 5000 4800 4600 4400 4200>,
			<4000 3800 3600 3400 3200 3000>,
			<2800 2600 2400 2200 2000 1800>,
			<1600 1400 1200 1000 900 800>,
			<700 600 500 400 300 200>,
			<100 0>;
		qcom,lut-data = <6387 5774 5317 5112 5054 5039>,
			<6411 5795 5320 5111 5053 5039>,
			<6428 5812 5324 5111 5053 5039>,
			<6437 5825 5327 5111 5053 5039>,
			<6442 5832 5330 5112 5054 5040>,
			<6443 5834 5331 5112 5055 5040>,
			<6439 5829 5330 5114 5056 5042>,
			<6429 5822 5329 5115 5058 5043>,
			<6412 5817 5329 5117 5060 5044>,
			<6381 5813 5332 5119 5061 5046>,
			<6369 5812 5334 5122 5064 5048>,
			<6420 5844 5337 5126 5067 5050>,
			<6476 5880 5341 5131 5070 5052>,
			<6446 5873 5355 5137 5073 5055>,
			<6336 5837 5382 5144 5077 5059>,
			<6270 5799 5392 5152 5080 5062>,
			<6242 5757 5384 5160 5085 5065>,
			<6227 5722 5373 5168 5090 5068>,
			<6231 5707 5366 5181 5099 5075>,
			<6242 5698 5358 5196 5110 5083>,
			<6244 5686 5345 5196 5111 5084>,
			<6237 5667 5312 5166 5099 5076>,
			<6231 5652 5283 5134 5084 5065>,
			<6231 5645 5271 5117 5069 5054>,
			<6236 5640 5264 5104 5056 5043>,
			<6245 5639 5261 5102 5054 5041>,
			<6273 5638 5261 5103 5054 5042>,
			<6307 5638 5261 5104 5055 5042>,
			<6341 5647 5264 5106 5057 5045>,
			<6379 5671 5269 5109 5061 5048>,
			<6419 5697 5271 5113 5064 5051>,
			<6462 5727 5271 5118 5068 5055>,
			<6509 5761 5272 5122 5073 5058>,
			<6559 5800 5278 5125 5078 5064>,
			<6613 5845 5288 5127 5083 5068>,
			<6673 5893 5296 5127 5079 5064>,
			<6740 5947 5305 5124 5067 5050>,
			<6813 6009 5315 5122 5060 5044>,
			<6893 6082 5328 5117 5057 5043>,
			<6978 6167 5342 5113 5056 5043>,
			<7070 6263 5358 5114 5058 5044>,
			<7171 6377 5375 5119 5062 5047>,
			<7283 6510 5400 5123 5063 5048>,
			<7405 6670 5428 5125 5062 5047>,
			<7460 6806 5437 5119 5055 5041>,
			<7557 6935 5466 5125 5060 5047>,
			<7667 7081 5510 5134 5068 5052>,
			<7794 7244 5568 5145 5073 5058>,
			<7924 7388 5641 5155 5081 5069>,
			<8062 7523 5723 5173 5091 5072>,
			<8242 7618 5792 5173 5076 5056>,
			<8750 7710 5851 5170 5075 5055>,
			<9655 7965 5997 5194 5082 5063>,
			<11188 8777 6283 5238 5102 5081>,
			<11188 8777 6283 5238 5102 5081>,
			<11188 8777 6283 5238 5102 5081>;
	};

};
